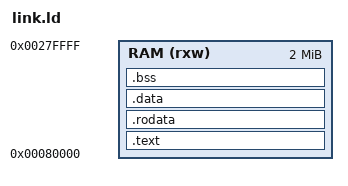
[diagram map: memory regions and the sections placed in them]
ENTRY(_start)

MEMORY
{
    RAM (rxw) : ORIGIN = 0x80000, LENGTH = 2M
}

SECTIONS
{
    .text : {
        *(.text*)
    } > RAM

    .rodata : {
        *(.rodata*)
    } > RAM

    .data : {
        *(.data*)
    } > RAM

    .bss : {
        *(.bss*)
    } > RAM
}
